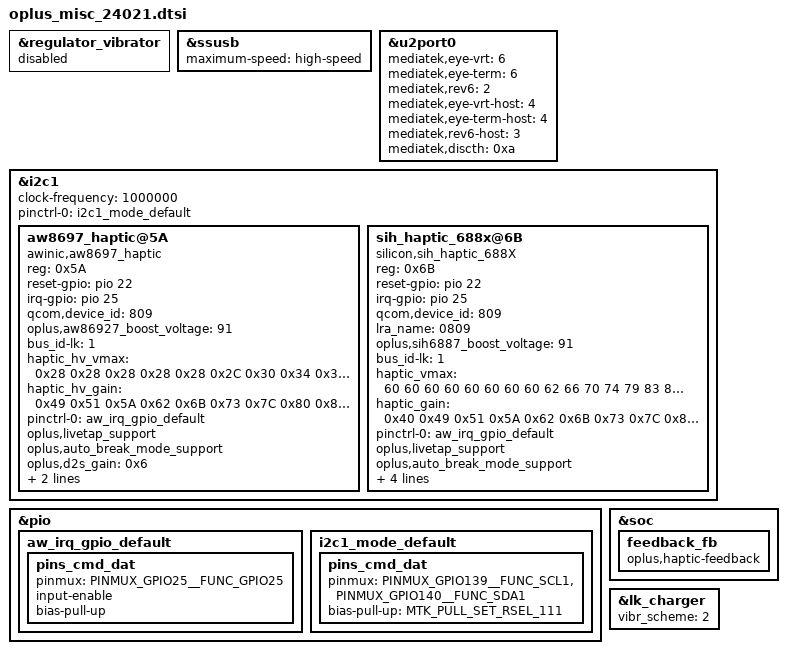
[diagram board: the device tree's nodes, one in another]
// SPDX-License-Identifier: GPL-2.0-only
/*
* Copyright (C) 2021-2020 Oplus. All rights reserved.
*/
#include <dt-bindings/iio/mt635x-auxadc.h>
#include <dt-bindings/pinctrl/mt6373-pinfunc.h>
#include <dt-bindings/pinctrl/mt65xx.h>


/* charge start */
&regulator_vibrator{
	status = "disabled";
};

&ssusb {
	maximum-speed = "high-speed";
};

&u2port0 {
	mediatek,eye-vrt = <6>;
	mediatek,eye-term = <6>;
	mediatek,rev6 = <2>;
	mediatek,eye-vrt-host = <4>;
	mediatek,eye-term-host = <4>;
	mediatek,rev6-host = <3>;
	mediatek,discth = <0xa>;
};

&i2c1 {
	status = "okay";
	clock-frequency = <1000000>;

	// AWINIC AW8697 Haptic
	aw8697_haptic@5A {
		status = "okay";
		compatible = "awinic,aw8697_haptic";
		reg = <0x5A>;
		reset-gpio = <&pio 22 0x00>;
		irq-gpio = <&pio 25 0x00>;
		qcom,device_id = <809>;
		oplus,aw86927_boost_voltage = <91>; /* 9.1v */
		bus_id-lk = <1>;

		haptic_hv_vmax = /bits/ 8 < 0x28 0x28 0x28 0x28 0x28 0x2C 0x30 0x34 0x38 0x3C 0x40 0x44 0x48 0x4C 0x50 0x54 0x58 >;
		haptic_hv_gain = /bits/ 8 < 0x49 0x51 0x5A 0x62 0x6B 0x73 0x7C 0x80 0x80 0x80 0x80 0x80 0x80 0x80 0x80 0x80 0x80 >;

		pinctrl-names = "irq_active";
		pinctrl-0 = <&aw_irq_gpio_default>;
		oplus,livetap_support;
		oplus,auto_break_mode_support;
		oplus,d2s_gain = /bits/ 8 <0x6>;
		oplus,brk_time = /bits/ 8 <0x6>;
		oplus,brk_gain = /bits/ 8 <0x8>;
	};

	sih_haptic_688x@6B {
		status = "okay";
		compatible = "silicon,sih_haptic_688X";
		reg = <0x6B>;
		reset-gpio = <&pio 22 0x00>;
		irq-gpio = <&pio 25 0x00>;
		qcom,device_id = <809>;
		lra_name = "0809";
		oplus,sih6887_boost_voltage = <91>; /* 9.1v */
		bus_id-lk = <1>;

		haptic_vmax = /bits/ 8 < 60 60 60 60 60 60 60 60 62 66 70 74 79 83 86 90 91 >;
		haptic_gain = /bits/ 8 < 0x40 0x49 0x51 0x5A 0x62 0x6B 0x73 0x7C 0x80 0x80 0x80 0x80 0x80 0x80 0x80 0x80 0x80 >;

		pinctrl-names = "irq_active";
		pinctrl-0 = <&aw_irq_gpio_default>;
		oplus,livetap_support;
		oplus,auto_break_mode_support;
		/* kernel brk config*/
		oplus,brk_addr_regs = /bits/ 8 < 0x98 0x99 0xAD 0xAE 0x85 >;
		oplus,brk_addr_val = /bits/ 8 < 0x33 0x0B 0xD7 0x0E 0x05 >;
		/* lk brk config*/
		brk_addr_regs-lk = /bits/ 8 < 0x98 0x99 0xAD 0xAE >;
		brk_addr_val-lk = /bits/ 8 < 0x66 0x0A 0xC3 0x17 >;
	};
};

&i2c1 {
	pinctrl-names = "default";
	pinctrl-0 = <&i2c1_mode_default>;
};

&pio{
	aw_irq_gpio_default: aw_irq_gpio_default {
		pins_cmd_dat {
			pinmux = <PINMUX_GPIO25__FUNC_GPIO25>;
			input-enable;
			bias-pull-up;
		};
	};

	i2c1_mode_default: i2c1_mode_default {
		pins_cmd_dat {
			pinmux = <PINMUX_GPIO139__FUNC_SCL1>,
				 <PINMUX_GPIO140__FUNC_SDA1>;
			bias-pull-up = <MTK_PULL_SET_RSEL_111>;
		};
	};
};

&soc {
	feedback_fb: feedback_fb {
		compatible = "oplus,haptic-feedback";
	};
};

&lk_charger {
	/*0:pmic_vib 1:gpio_vib 2:si_vib 3:aw_vib*/
	vibr_scheme = <2>;
};
